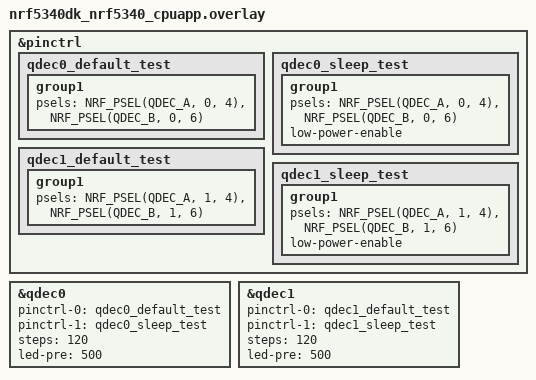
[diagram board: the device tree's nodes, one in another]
/*
 * Copyright (c) 2026 Nordic Semiconductor ASA
 *
 * SPDX-License-Identifier: LicenseRef-Nordic-5-Clause
 */

&pinctrl {
	qdec0_default_test: qdec0_default_test {
		group1 {
			psels = <NRF_PSEL(QDEC_A, 0, 4)>,
				<NRF_PSEL(QDEC_B, 0, 6)>;
		};
	};

	qdec0_sleep_test: qdec0_sleep_test {
		group1 {
			psels = <NRF_PSEL(QDEC_A, 0, 4)>,
				<NRF_PSEL(QDEC_B, 0, 6)>;
			low-power-enable;
		};
	};

	qdec1_default_test: qdec1_default_test {
		group1 {
			psels = <NRF_PSEL(QDEC_A, 1, 4)>,
				<NRF_PSEL(QDEC_B, 1, 6)>;
		};
	};

	qdec1_sleep_test: qdec1_sleep_test {
		group1 {
			psels = <NRF_PSEL(QDEC_A, 1, 4)>,
				<NRF_PSEL(QDEC_B, 1, 6)>;
			low-power-enable;
		};
	};
};

&qdec0 {
	status = "okay";
	pinctrl-0 = <&qdec0_default_test>;
	pinctrl-1 = <&qdec0_sleep_test>;
	pinctrl-names = "default", "sleep";
	steps = <120>;
	led-pre = <500>;
};

&qdec1 {
	status = "okay";
	pinctrl-0 = <&qdec1_default_test>;
	pinctrl-1 = <&qdec1_sleep_test>;
	pinctrl-names = "default", "sleep";
	steps = <120>;
	led-pre = <500>;
};
